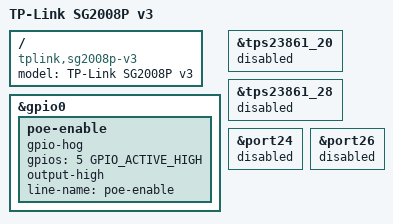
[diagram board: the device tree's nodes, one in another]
// SPDX-License-Identifier: GPL-2.0-or-later

#include "rtl8380_tplink_sg2xxx.dtsi"

/ {
	compatible = "tplink,sg2008p-v3", "realtek,rtl838x-soc";
	model = "TP-Link SG2008P v3";
};

&gpio0 {
	poe-enable {
		gpio-hog;
		gpios = <5 GPIO_ACTIVE_HIGH>;
		output-high;
		line-name = "poe-enable";
	};
};

&tps23861_20 {
	status = "disabled";
};

&tps23861_28 {
	status = "disabled";
};

&port24 {
	status = "disabled";
};

&port26 {
	status = "disabled";
};
